# STC32G144K246 register map
Vendor: STC; File version: 2.0
Registers are 8-bit, read-write, no defined reset value unless marked. A register's access mark holds for its fields unless they carry their own. Offsets are from the block's base; [hi:lo] are bit positions.

## Interrupts — 核心和扩展中断控制
Base 0x1000008F
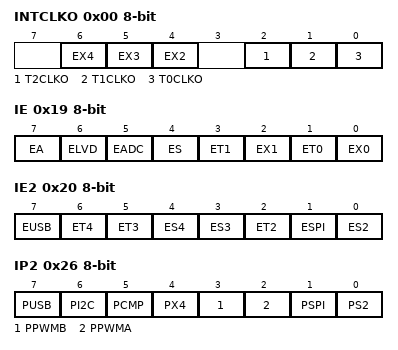
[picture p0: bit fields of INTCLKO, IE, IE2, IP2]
0x00 INTCLKO ro — 中断与时钟输出控制寄存器
  [6] EX4 — 外部中断4 中断允许位。
    0=禁止INT4 中断; 1=允许INT4 中断
  [5] EX3 — 外部中断3 中断允许位。
    0=禁止INT3 中断; 1=允许INT3 中断
  [4] EX2 — 外部中断2 中断允许位。
    0=禁止INT2 中断; 1=允许INT2 中断
  [2] T2CLKO — 定时器2时钟输出控制
    0=关闭时钟输出; 1=使能P1.3 口的是定时器2 时钟输出功能
  [1] T1CLKO — 定时器1时钟输出控制
    0=关闭时钟输出; 1=使能P3.4 口的是定时器1 时钟输出功能
  [0] T0CLKO — 定时器0时钟输出控制
    0=关闭时钟输出; 1=使能P3.5 口的是定时器0 时钟输出功能
0x19 IE — 中断允许寄存器
  [7] EA — 总中断允许控制位。EA 的作用是使中断允许形成多级控制。 即各中断源首先受EA 控制;其次还受各中断源自己的中断允许控制位控制。
    0=CPU 屏蔽所有的中断申请; 1=CPU 开放中断
  [6] ELVD — 低压检测中断允许位。
    0=禁止低压检测中断; 1=允许低压检测中断
  [5] EADC — A/D 转换中断允许位。
    0=禁止A/D 转换中断; 1=允许A/D 转换中断
  [4] ES — 串口1 中断允许位。
    0=禁止串口1 中断; 1=允许串口1 中断
  [3] ET1 — 定时/计数器T1 的溢出中断允许位。
    0=禁止T1 中断; 1=允许T1 中断
  [2] EX1 — 外部中断1 中断允许位。
    0=禁止INT1 中断; 1=允许INT1 中断
  [1] ET0 — 定时/计数器T0 的溢出中断允许位。
    0=禁止T0 中断; 1=允许T0 中断
  [0] EX0 — 外部中断0 中断允许位。
    0=禁止INT0 中断; 1=允许INT0 中断
0x20 IE2 — 中断允许寄存器2
  [7] EUSB — USB 中断允许位。
    0=禁止USB 中断; 1=允许USB 中断。打开USB 中断总开关后，还需要使能USB 的IN/OUT 端点中断才能产生USB
  [6] ET4 — 定时/计数器T4 的溢出中断允许位。
    0=禁止T4 中断; 1=允许T4 中断
  [5] ET3 — 定时/计数器T3 的溢出中断允许位。
    0=禁止T3 中断; 1=允许T3 中断
  [4] ES4 — 串口4 中断允许位。
    0=禁止串口4 中断; 1=允许串口4 中断
  [3] ES3 — 串口3 中断允许位。
    0=禁止串口3 中断; 1=允许串口3 中断
  [2] ET2 — 定时/计数器T2 的溢出中断允许位。
    0=禁止T2 中断; 1=允许T2 中断
  [1] ESPI — SPI 中断允许位。
    0=禁止SPI 中断; 1=允许SPI 中断
  [0] ES2 — 串口2 中断允许位。
    0=禁止串口2 中断; 1=允许串口2 中断
0x26 IP2 — 中断优先级控制寄存器2
  [7] PUSB — 尚未自动匹配到此字段的独立说明；请查看下方章节说明。
  [6] PI2C — 尚未自动匹配到此字段的独立说明；请查看下方章节说明。
  [5] PCMP — 尚未自动匹配到此字段的独立说明；请查看下方章节说明。
  [4] PX4 — 尚未自动匹配到此字段的独立说明；请查看下方章节说明。
  [3] PPWMB — 尚未自动匹配到此字段的独立说明；请查看下方章节说明。
  [2] PPWMA — 尚未自动匹配到此字段的独立说明；请查看下方章节说明。
  [1] PSPI — 尚未自动匹配到此字段的独立说明；请查看下方章节说明。
  [0] PS2 — 尚未自动匹配到此字段的独立说明；请查看下方章节说明。
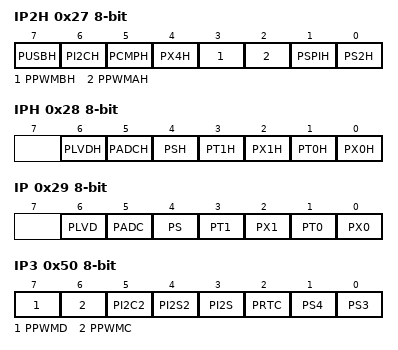
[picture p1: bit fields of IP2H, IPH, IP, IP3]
0x27 IP2H — 高中断优先级控制寄存器2
  [7] PUSBH — 尚未自动匹配到此字段的独立说明；请查看下方章节说明。
  [6] PI2CH — 尚未自动匹配到此字段的独立说明；请查看下方章节说明。
  [5] PCMPH — 尚未自动匹配到此字段的独立说明；请查看下方章节说明。
  [4] PX4H — 尚未自动匹配到此字段的独立说明；请查看下方章节说明。
  [3] PPWMBH — 尚未自动匹配到此字段的独立说明；请查看下方章节说明。
  [2] PPWMAH — 尚未自动匹配到此字段的独立说明；请查看下方章节说明。
  [1] PSPIH — 尚未自动匹配到此字段的独立说明；请查看下方章节说明。
  [0] PS2H — 尚未自动匹配到此字段的独立说明；请查看下方章节说明。
0x28 IPH — 高中断优先级控制寄存器
  [6] PLVDH — 尚未自动匹配到此字段的独立说明；请查看下方章节说明。
  [5] PADCH — 尚未自动匹配到此字段的独立说明；请查看下方章节说明。
  [4] PSH — 尚未自动匹配到此字段的独立说明；请查看下方章节说明。
  [3] PT1H — 尚未自动匹配到此字段的独立说明；请查看下方章节说明。
  [2] PX1H — 尚未自动匹配到此字段的独立说明；请查看下方章节说明。
  [1] PT0H — 尚未自动匹配到此字段的独立说明；请查看下方章节说明。
  [0] PX0H — 尚未自动匹配到此字段的独立说明；请查看下方章节说明。
0x29 IP — 中断优先级控制寄存器
  [6] PLVD — 尚未自动匹配到此字段的独立说明；请查看下方章节说明。
  [5] PADC — 尚未自动匹配到此字段的独立说明；请查看下方章节说明。
  [4] PS — 尚未自动匹配到此字段的独立说明；请查看下方章节说明。
  [3] PT1 — 尚未自动匹配到此字段的独立说明；请查看下方章节说明。
  [2] PX1 — 尚未自动匹配到此字段的独立说明；请查看下方章节说明。
  [1] PT0 — 尚未自动匹配到此字段的独立说明；请查看下方章节说明。
  [0] PX0 — 尚未自动匹配到此字段的独立说明；请查看下方章节说明。
0x50 IP3 — 中断优先级控制寄存器3
  [7] PPWMD — 尚未自动匹配到此字段的独立说明；请查看下方章节说明。
  [6] PPWMC — 尚未自动匹配到此字段的独立说明；请查看下方章节说明。
  [5] PI2C2 — 尚未自动匹配到此字段的独立说明；请查看下方章节说明。
  [4] PI2S2 — 尚未自动匹配到此字段的独立说明；请查看下方章节说明。
  [3] PI2S — 尚未自动匹配到此字段的独立说明；请查看下方章节说明。
  [2] PRTC — 尚未自动匹配到此字段的独立说明；请查看下方章节说明。
  [1] PS4 — 尚未自动匹配到此字段的独立说明；请查看下方章节说明。
  [0] PS3 — 尚未自动匹配到此字段的独立说明；请查看下方章节说明。
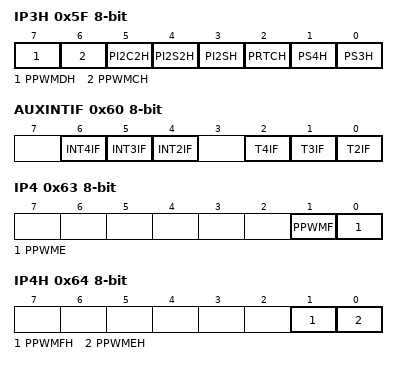
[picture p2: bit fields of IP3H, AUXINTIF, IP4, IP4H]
0x5F IP3H — 高中断优先级控制寄存器3
  [7] PPWMDH — 尚未自动匹配到此字段的独立说明；请查看下方章节说明。
  [6] PPWMCH — 尚未自动匹配到此字段的独立说明；请查看下方章节说明。
  [5] PI2C2H — 尚未自动匹配到此字段的独立说明；请查看下方章节说明。
  [4] PI2S2H — 尚未自动匹配到此字段的独立说明；请查看下方章节说明。
  [3] PI2SH — 尚未自动匹配到此字段的独立说明；请查看下方章节说明。
  [2] PRTCH — 尚未自动匹配到此字段的独立说明；请查看下方章节说明。
  [1] PS4H — 尚未自动匹配到此字段的独立说明；请查看下方章节说明。
  [0] PS3H — 尚未自动匹配到此字段的独立说明；请查看下方章节说明。
0x60 AUXINTIF ro — 扩展外部中断标志寄存器
  [6] INT4IF — 外部中断4中断请求标志。中断服务程序中，硬件自动清零。
  [5] INT3IF — 外部中断3中断请求标志。中断服务程序中，硬件自动清零。
  [4] INT2IF — 外部中断2中断请求标志。中断服务程序中，硬件自动清零。
  [2] T4IF — 定时器4溢出中断标志。中断服务程序中，硬件自动清零。
  [1] T3IF — 定时器3溢出中断标志。中断服务程序中，硬件自动清零。
  [0] T2IF — 定时器2溢出中断标志。中断服务程序中，硬件自动清零。
0x63 IP4 — 中断优先级控制寄存器4
  [1] PPWMF — 尚未自动匹配到此字段的独立说明；请查看下方章节说明。
  [0] PPWME — 尚未自动匹配到此字段的独立说明；请查看下方章节说明。
0x64 IP4H — 高中断优先级控制寄存器4
  [1] PPWMFH — 尚未自动匹配到此字段的独立说明；请查看下方章节说明。
  [0] PPWMEH — 尚未自动匹配到此字段的独立说明；请查看下方章节说明。
